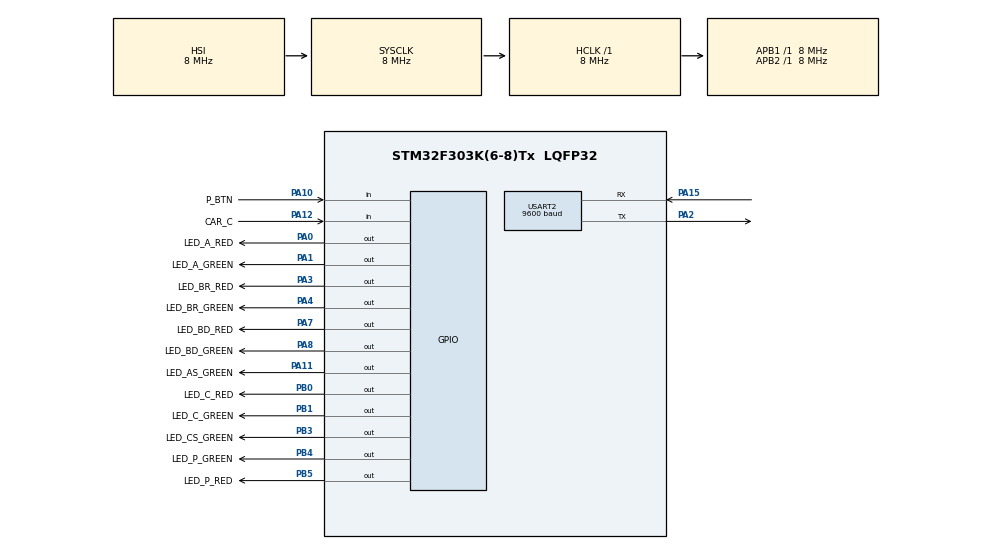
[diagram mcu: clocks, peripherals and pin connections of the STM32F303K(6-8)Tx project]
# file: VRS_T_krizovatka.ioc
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Mcu.Family=STM32F3
Mcu.Name=STM32F303K(6-8)Tx
Mcu.Package=LQFP32
NVIC.PriorityGroup=NVIC_PRIORITYGROUP_4
NVIC.USART2_IRQn=true\:0\:0\:false\:false\:true\:true\:true\:true
PA0.GPIO_Label=LED_A_RED
PA0.PinState=GPIO_PIN_RESET
PA0.Signal=GPIO_Output
PA1.GPIO_Label=LED_A_GREEN
PA1.Signal=GPIO_Output
PA10.GPIO_Label=P_BTN
PA10.GPIO_PuPd=GPIO_PULLUP
PA10.Signal=GPIO_Input
PA11.GPIO_Label=LED_AS_GREEN
PA11.Signal=GPIO_Output
PA12.GPIO_Label=CAR_C
PA12.GPIO_PuPd=GPIO_PULLUP
PA12.Signal=GPIO_Input
PA13.GPIO_Label=SWDIO
PA13.Mode=Serial_Wire
PA13.Signal=SYS_JTMS-SWDIO
PA14.GPIO_Label=SWCLK
PA14.Mode=Serial_Wire
PA14.Signal=SYS_JTCK-SWCLK
PA15.Mode=Asynchronous
PA15.Signal=USART2_RX
PA2.Mode=Asynchronous
PA2.Signal=USART2_TX
PA3.GPIO_Label=LED_BR_RED
PA3.PinState=GPIO_PIN_RESET
PA3.Signal=GPIO_Output
PA4.GPIO_Label=LED_BR_GREEN
PA4.PinState=GPIO_PIN_RESET
PA4.Signal=GPIO_Output
PA7.GPIO_Label=LED_BD_RED
PA7.Signal=GPIO_Output
PA8.GPIO_Label=LED_BD_GREEN
PA8.Signal=GPIO_Output
PB0.GPIO_Label=LED_C_RED
PB0.Signal=GPIO_Output
PB1.GPIO_Label=LED_C_GREEN
PB1.Signal=GPIO_Output
PB3.GPIO_Label=LED_CS_GREEN
PB3.Signal=GPIO_Output
PB4.GPIO_Label=LED_P_GREEN
PB4.Signal=GPIO_Output
PB5.GPIO_Label=LED_P_RED
PB5.Signal=GPIO_Output
PF0\ /\ OSC_IN.GPIO_Label=MCO
PF0\ /\ OSC_IN.Mode=HSE-External-Clock-Source
PF0\ /\ OSC_IN.Signal=RCC_OSC_IN
ProjectManager.HeapSize=0x200
ProjectManager.StackSize=0x400
ProjectManager.TargetToolchain=STM32CubeIDE
RCC.AHBFreq_Value=8000000
RCC.APB1Freq_Value=8000000
RCC.APB2Freq_Value=8000000
RCC.CortexFreq_Value=8000000
RCC.HSE_VALUE=8000000
RCC.HSI_VALUE=8000000
RCC.SYSCLKFreq_VALUE=8000000
USART2.BaudRate=9600
USART2.VirtualMode-Asynchronous=VM_ASYNC
board=NUCLEO-F303K8

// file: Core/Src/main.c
/* USER CODE BEGIN Header */
/**
  ******************************************************************************
  * @file           : main.c
  * @brief          : Main program body
  ******************************************************************************
  * @attention
  *
  * Copyright (c) 2026 STMicroelectronics.
  * All rights reserved.
  *
  * This software is licensed under terms that can be found in the LICENSE file
  * in the root directory of this software component.
  * If no LICENSE file comes with this software, it is provided AS-IS.
  *
  ******************************************************************************
  */
/* USER CODE END Header */
#include "main.h"
#include "usart.h"
#include "gpio.h"

/* USER CODE BEGIN Includes */
#include "traffic_gpio.h"
#include "traffic_fsm.h"
/* USER CODE END Includes */

void SystemClock_Config(void);

int main(void)
{

  /* MCU Configuration--------------------------------------------------------*/

  /* Reset of all peripherals, Initializes the Flash interface and the Systick. */
  HAL_Init();

  /* Configure the system clock */
  SystemClock_Config();

  /* Initialize all configured peripherals */
  MX_GPIO_Init();
  MX_USART2_UART_Init();
  /* USER CODE BEGIN 2 */
  TrafficGpio_Init();
  TrafficFsm_RegisterPhaseCallback(TrafficGpio_Apply);   /* registracia pred spustenim automatu */
  TrafficFsm_Init(HAL_GetTick());
  /* USER CODE END 2 */

  /* Infinite loop */
  while (1)
  {

    /* USER CODE BEGIN 3 */
    /* stavovy automat vyhodnoti casovanie, zmenu fazy oznami GPIO cez callback */
    TrafficFsm_Update(HAL_GetTick());
  }
  /* USER CODE END 3 */
}

void SystemClock_Config(void)
{
  RCC_OscInitTypeDef RCC_OscInitStruct = {0};
  RCC_ClkInitTypeDef RCC_ClkInitStruct = {0};

  /** Initializes the RCC Oscillators according to the specified parameters
  * in the RCC_OscInitTypeDef structure.
  */
  RCC_OscInitStruct.OscillatorType = RCC_OSCILLATORTYPE_HSI;
  RCC_OscInitStruct.HSIState = RCC_HSI_ON;
  RCC_OscInitStruct.HSICalibrationValue = RCC_HSICALIBRATION_DEFAULT;
  RCC_OscInitStruct.PLL.PLLState = RCC_PLL_NONE;
  if (HAL_RCC_OscConfig(&RCC_OscInitStruct) != HAL_OK)
  {
    Error_Handler();
  }

  /** Initializes the CPU, AHB and APB buses clocks
  */
  RCC_ClkInitStruct.ClockType = RCC_CLOCKTYPE_HCLK|RCC_CLOCKTYPE_SYSCLK
                              |RCC_CLOCKTYPE_PCLK1|RCC_CLOCKTYPE_PCLK2;
  RCC_ClkInitStruct.SYSCLKSource = RCC_SYSCLKSOURCE_HSI;
  RCC_ClkInitStruct.AHBCLKDivider = RCC_SYSCLK_DIV1;
  RCC_ClkInitStruct.APB1CLKDivider = RCC_HCLK_DIV1;
  RCC_ClkInitStruct.APB2CLKDivider = RCC_HCLK_DIV1;

  if (HAL_RCC_ClockConfig(&RCC_ClkInitStruct, FLASH_LATENCY_0) != HAL_OK)
  {
    Error_Handler();
  }
}

void Error_Handler(void)
{
  __disable_irq();
  while (1)
  {
  }
}
